# RN8XXX_V2 register map
File version: 1.0
Renergy Metering MCU RN8XXX V2
Registers are 32-bit, read-write, reset 0x0 unless marked. A register's access mark holds for its fields unless they carry their own. Offsets are from the block's base; lines under a group give offsets from that group; [hi:lo] are bit positions; {n}, {i} and the like mark numbered series; 'fields as' and 'values as' point back to an identical list; <NAME> marks a mode.

## Memory map
0x40000000 UART0 size 0x40 — UART tranceiver
0x40004000 UART1 size 0x40
0x40008000 UART2 size 0x40
0x4000C000 UART3 size 0x40
0x40010000 Timer0 size 0x33 — A 32-bit timer
0x40014000 Timer1 size 0x33
0x40018000 UART4 size 0x40
0x4001C000 UART5 size 0x40
0x40020000 SPI0 size 0x38 — synchronous peripheral interface
0x40024000 I2C size 0x13 — I2C controller
0x40028000 KBI size 0xF — key detection
0x4002C000 analog size 0x44 — analog peripherals
0x40030000 WDT size 0x20 — watchdog timer
0x40034000 SYSTEM_CONTROL size 0xF8
0x40038000 ISO7816 size 0x23 — ISO7816 interface
0x4003C000 RTC size 0x130 — real time clock
0x40044000 INTC size 0xF — interrupt controller for off-chip interrupt requests
0x40048000 LCD size 0x46 — liquid crystal display
0x40050000 SPI1 size 0x38
0x40054000 SPI2 size 0x38
0x40058000 SPI3 size 0x38
0x4005C000 d2f size 0x70 — Energy Digital Integrator frequency converter
0x40060000 simptc size 0x30
0x40068000 m2m size 0x20 — DMA memory access
0x50000000 GPIO size 0x110
0x5000C000 Coprocessor size 0x4000

## Interrupts
0 SYS (SYSTEM_CONTROL)
3 RTC
5 ADC (analog)
6 UART0
7 UART1
8 UART2
9 UART3
10 SPI0
11 I2C
12 ISO7816
13 SPI2
14 TC0 (Timer0)
15 TC1 (Timer1)
16 UART4
17 UART5
18 WDT
19 KBI
20 LCD
23 SPI1
25 simp_timer (simptc)
29 mem2mem (m2m)
33 Coprocessor

## Coprocessor
Base 0x5000C000
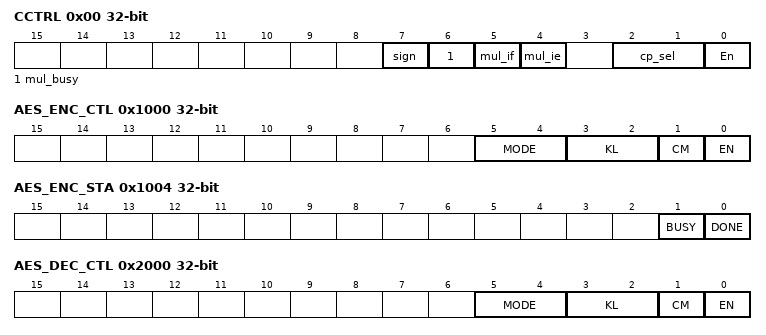
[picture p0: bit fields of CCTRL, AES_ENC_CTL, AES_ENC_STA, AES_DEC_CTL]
0x00 CCTRL — Coprocessor control register
  [7] sign ro — multiplication being busy
    0=no operation; 1=adder carry bit or subtraction borrow bit
  [6] mul_busy ro — multiplication being busy
    0=finished (multiplication being finished); 1=busy (Multiplier is busy)
  [5] mul_if — multiplication interruption flag
    0=disable multiplication interrupt; 1=enalbe (ensable multiplication interrupt)
  [4] mul_ie — enable multiplication interrupt
    values as mul_if
  [2:1] cp_sel — configuration
    0=unsigned 192 bits multiply unsigned 32 bits; 1=unsigned 192 bits multiply unsigned 192 bits; 2=unsigned 192 bits add unsigned 192 bits; 3=unsigned 192 bits subtract unsigned 192 bits
  [0] En wo — Enalbe Multiplier.Set 1 to start multiplier ,only when cp_sel bits are configurated as multiplication.
{0x0+4i} CIN1_{i} (i=1..6) — Data register.For storing addend ,Subtrahend or Multiplier.
{0x18+4i} CIN2_{i} (i=1..6) — Data register.For storing Summand ,Minuend or Multiplicand.
{0x30+4i} RESULT_{i} (i=1..12) — Result register
0x1000 AES_ENC_CTL — Coprocessor control register
  [5:4] MODE — mode of moudle encryption selection
    0=ECB mode; 1=CBC mode; 2=CTR mode
  [3:2] KL — key length
    0=128bit; 1=192bit; 2=256bit
  [1] CM — enable continuous mode
    0=disable continuous mode; 1=enable continuous mode
  [0] EN — enable AES ENC
    0=disable AES ENC; 1=enable AES ENC
0x1004 AES_ENC_STA — Coprocessor control register
  [1] BUSY ro — status of encryption
    0=no action; 1=being encrypting
  [0] DONE ro — status of last encryption opration
    0=be doing or no action; 1=done
{0x1010+4i} AES_ENC_KEY{i} (i=0..7) — key register
{0x1030+4i} AES_ENC_PT{i} (i=0..3) — plaintext register
{0x1040+4i} AES_ENC_IV{i} (i=0..3) — Initial vector register
{0x1050+4i} AES_ENC_CT{i} (i=0..3) — Ciphertext register
0x2000 AES_DEC_CTL — Decryption control register
  [5:4] MODE — mode of moudle decryption selection
    0=ECB mode; 1=CBC mode; 2=CTR mode
  [3:2] KL — key length
    0=128bit; 1=192bit; 2=256bit
  [1] CM — enable continuous mode
    0=disable continuous mode; 1=enable continuous mode
  [0] EN — enable decryption
    0=disable; 1=enable
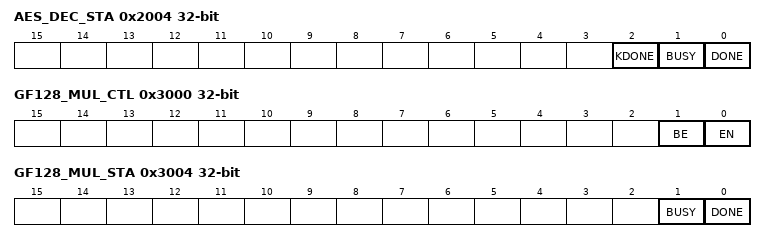
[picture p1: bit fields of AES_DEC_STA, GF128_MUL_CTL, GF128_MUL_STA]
0x2004 AES_DEC_STA — decryption register
  [2] KDONE ro — status of last opration
    0=hadn't finished; 1=done
  [1] BUSY ro — status of decryption
    0=no action; 1=being decryption
  [0] DONE ro — status of last decryption opration
    0=be doing or no action; 1=done
{0x2010+4i} AES_DEC_KEY{i} (i=0..7) — decryption key register
{0x2030+4i} AES_DEC_PT{i} (i=0..3) — plaintext register
{0x2040+4i} AES_DEC_IV{i} (i=0..3) — Initial vector register
{0x2050+4i} AES_DEC_CT{i} (i=0..3) — Ciphertext register
0x3000 GF128_MUL_CTL — GF128 multiplication control register
  [1] BE — bit enable
    0=disable; 1=enable
  [0] EN — enable module
    0=disable; 1=enable
0x3004 GF128_MUL_STA — GF128 multiplication status register
  [1] BUSY ro — status of multiplication
    0=no action; 1=being multiplication
  [0] DONE ro — status of last multiplication opration
    0=be doing or no action; 1=done
{0x3010+4i} GF128_MUL_HT{i} (i=0..3) — key register
{0x3020+4i} GF128_MUL_AT{i} (i=0..3) — initial vector register
{0x3030+4i} GF128_MUL_CT{i} (i=0..3) — input vector register
{0x3040+4i} GF128_MUL_RT{i} (i=0..3) — output vector register
